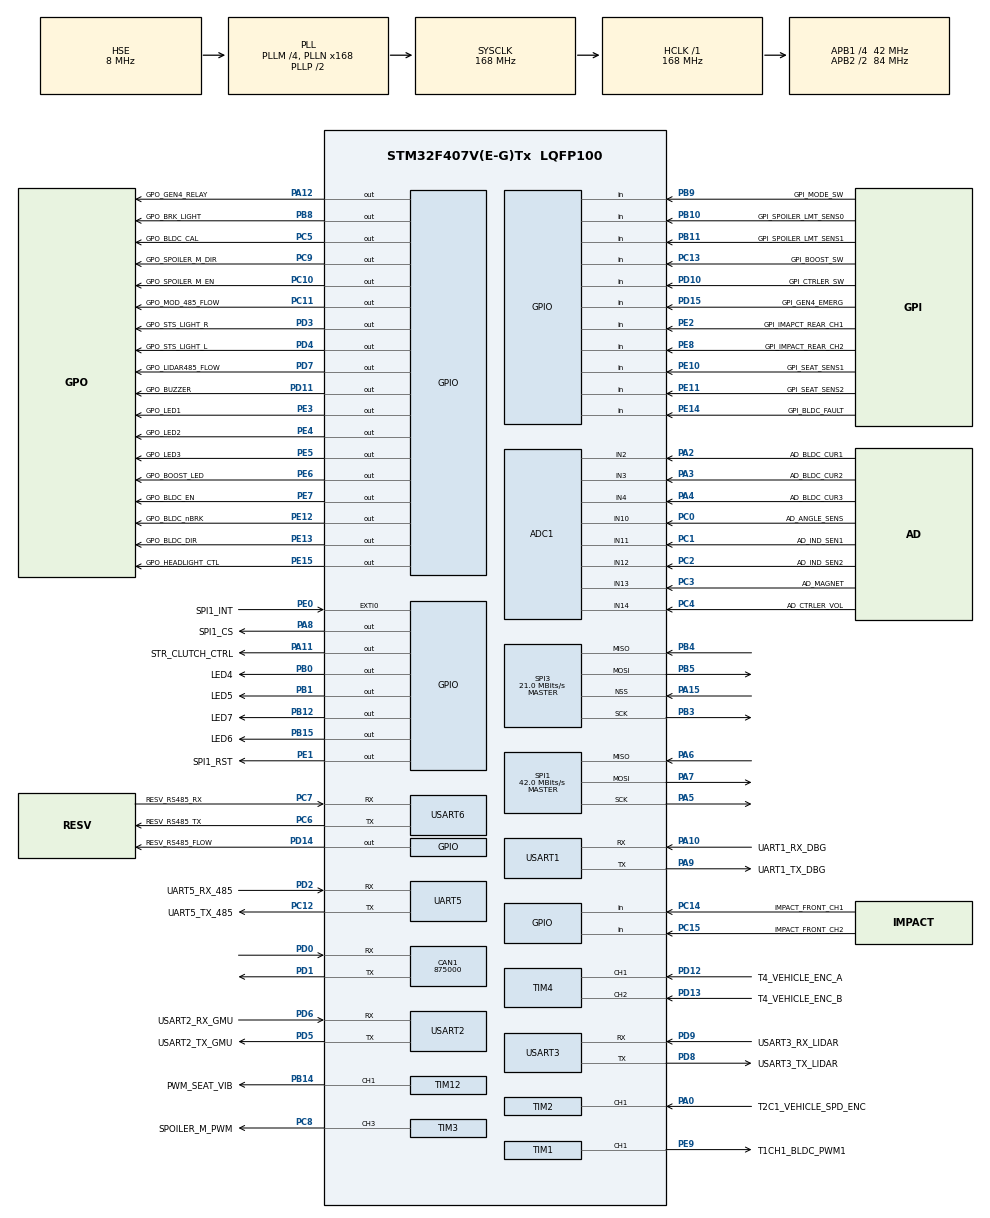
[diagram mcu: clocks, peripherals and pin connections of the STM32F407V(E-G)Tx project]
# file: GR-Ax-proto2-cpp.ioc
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ADC1.Channel-1\#ChannelRegularConversion=ADC_CHANNEL_2
ADC1.Channel-2\#ChannelRegularConversion=ADC_CHANNEL_3
ADC1.Channel-3\#ChannelRegularConversion=ADC_CHANNEL_4
ADC1.Channel-4\#ChannelRegularConversion=ADC_CHANNEL_11
ADC1.Channel-5\#ChannelRegularConversion=ADC_CHANNEL_12
ADC1.Channel-6\#ChannelRegularConversion=ADC_CHANNEL_14
ADC1.Channel-7\#ChannelRegularConversion=ADC_CHANNEL_TEMPSENSOR
ADC1.ContinuousConvMode=ENABLE
ADC1.DMAContinuousRequests=ENABLE
ADC1.DiscontinuousConvMode=DISABLE
ADC1.EOCSelection=ADC_EOC_SINGLE_CONV
ADC1.ExternalTrigConv=ADC_SOFTWARE_START
ADC1.NbrOfConversion=7
ADC1.NbrOfConversionFlag=1
ADC1.Rank-1\#ChannelRegularConversion=1
ADC1.Rank-2\#ChannelRegularConversion=2
ADC1.Rank-3\#ChannelRegularConversion=3
ADC1.Rank-4\#ChannelRegularConversion=4
ADC1.Rank-5\#ChannelRegularConversion=5
ADC1.Rank-6\#ChannelRegularConversion=6
ADC1.Rank-7\#ChannelRegularConversion=7
ADC1.SamplingTime-1\#ChannelRegularConversion=ADC_SAMPLETIME_112CYCLES
ADC1.SamplingTime-2\#ChannelRegularConversion=ADC_SAMPLETIME_112CYCLES
ADC1.SamplingTime-3\#ChannelRegularConversion=ADC_SAMPLETIME_112CYCLES
ADC1.SamplingTime-4\#ChannelRegularConversion=ADC_SAMPLETIME_112CYCLES
ADC1.SamplingTime-5\#ChannelRegularConversion=ADC_SAMPLETIME_112CYCLES
ADC1.SamplingTime-6\#ChannelRegularConversion=ADC_SAMPLETIME_112CYCLES
ADC1.SamplingTime-7\#ChannelRegularConversion=ADC_SAMPLETIME_112CYCLES
ADC1.master=1
CAN1.CalculateBaudRate=875000
CAN1.CalculateTimeBit=1142
CAN1.CalculateTimeQuantum=380.95238095238096
Dma.ADC1.0.Direction=DMA_PERIPH_TO_MEMORY
Dma.ADC1.0.FIFOMode=DMA_FIFOMODE_DISABLE
Dma.ADC1.0.Instance=DMA2_Stream4
Dma.ADC1.0.MemDataAlignment=DMA_MDATAALIGN_HALFWORD
Dma.ADC1.0.MemInc=DMA_MINC_ENABLE
Dma.ADC1.0.Mode=DMA_CIRCULAR
Dma.ADC1.0.PeriphDataAlignment=DMA_PDATAALIGN_HALFWORD
Dma.ADC1.0.PeriphInc=DMA_PINC_DISABLE
Dma.ADC1.0.Priority=DMA_PRIORITY_MEDIUM
Dma.Request0=ADC1
Dma.Request1=USART1_RX
Dma.Request10=UART5_TX
Dma.Request2=USART2_RX
Dma.Request3=USART3_RX
Dma.Request4=USART6_RX
Dma.Request5=USART1_TX
Dma.Request6=USART2_TX
Dma.Request7=USART3_TX
Dma.Request8=USART6_TX
Dma.Request9=UART5_RX
Dma.UART5_RX.9.Direction=DMA_PERIPH_TO_MEMORY
Dma.UART5_RX.9.FIFOMode=DMA_FIFOMODE_DISABLE
Dma.UART5_RX.9.Instance=DMA1_Stream0
Dma.UART5_RX.9.MemDataAlignment=DMA_MDATAALIGN_BYTE
Dma.UART5_RX.9.MemInc=DMA_MINC_ENABLE
Dma.UART5_RX.9.Mode=DMA_NORMAL
Dma.UART5_RX.9.PeriphDataAlignment=DMA_PDATAALIGN_BYTE
Dma.UART5_RX.9.PeriphInc=DMA_PINC_DISABLE
Dma.UART5_RX.9.Priority=DMA_PRIORITY_LOW
Dma.UART5_TX.10.Direction=DMA_MEMORY_TO_PERIPH
Dma.UART5_TX.10.FIFOMode=DMA_FIFOMODE_DISABLE
Dma.UART5_TX.10.Instance=DMA1_Stream7
Dma.UART5_TX.10.MemDataAlignment=DMA_MDATAALIGN_BYTE
Dma.UART5_TX.10.MemInc=DMA_MINC_ENABLE
Dma.UART5_TX.10.Mode=DMA_NORMAL
Dma.UART5_TX.10.PeriphDataAlignment=DMA_PDATAALIGN_BYTE
Dma.UART5_TX.10.PeriphInc=DMA_PINC_DISABLE
Dma.UART5_TX.10.Priority=DMA_PRIORITY_LOW
Dma.USART1_RX.1.Direction=DMA_PERIPH_TO_MEMORY
Dma.USART1_RX.1.FIFOMode=DMA_FIFOMODE_DISABLE
Dma.USART1_RX.1.Instance=DMA2_Stream2
Dma.USART1_RX.1.MemDataAlignment=DMA_MDATAALIGN_BYTE
Dma.USART1_RX.1.MemInc=DMA_MINC_ENABLE
Dma.USART1_RX.1.Mode=DMA_NORMAL
Dma.USART1_RX.1.PeriphDataAlignment=DMA_PDATAALIGN_BYTE
Dma.USART1_RX.1.PeriphInc=DMA_PINC_DISABLE
Dma.USART1_RX.1.Priority=DMA_PRIORITY_LOW
Dma.USART1_TX.5.Direction=DMA_MEMORY_TO_PERIPH
Dma.USART1_TX.5.FIFOMode=DMA_FIFOMODE_DISABLE
Dma.USART1_TX.5.Instance=DMA2_Stream7
Dma.USART1_TX.5.MemDataAlignment=DMA_MDATAALIGN_BYTE
Dma.USART1_TX.5.MemInc=DMA_MINC_ENABLE
Dma.USART1_TX.5.Mode=DMA_NORMAL
Dma.USART1_TX.5.PeriphDataAlignment=DMA_PDATAALIGN_BYTE
Dma.USART1_TX.5.PeriphInc=DMA_PINC_DISABLE
Dma.USART1_TX.5.Priority=DMA_PRIORITY_LOW
Dma.USART2_RX.2.Direction=DMA_PERIPH_TO_MEMORY
Dma.USART2_RX.2.FIFOMode=DMA_FIFOMODE_DISABLE
Dma.USART2_RX.2.Instance=DMA1_Stream5
Dma.USART2_RX.2.MemDataAlignment=DMA_MDATAALIGN_BYTE
Dma.USART2_RX.2.MemInc=DMA_MINC_ENABLE
Dma.USART2_RX.2.Mode=DMA_CIRCULAR
Dma.USART2_RX.2.PeriphDataAlignment=DMA_PDATAALIGN_BYTE
Dma.USART2_RX.2.PeriphInc=DMA_PINC_DISABLE
Dma.USART2_RX.2.Priority=DMA_PRIORITY_LOW
Dma.USART2_TX.6.Direction=DMA_MEMORY_TO_PERIPH
Dma.USART2_TX.6.FIFOMode=DMA_FIFOMODE_DISABLE
Dma.USART2_TX.6.Instance=DMA1_Stream6
Dma.USART2_TX.6.MemDataAlignment=DMA_MDATAALIGN_BYTE
Dma.USART2_TX.6.MemInc=DMA_MINC_ENABLE
Dma.USART2_TX.6.Mode=DMA_NORMAL
Dma.USART2_TX.6.PeriphDataAlignment=DMA_PDATAALIGN_BYTE
Dma.USART2_TX.6.PeriphInc=DMA_PINC_DISABLE
Dma.USART2_TX.6.Priority=DMA_PRIORITY_LOW
Dma.USART3_RX.3.Direction=DMA_PERIPH_TO_MEMORY
Dma.USART3_RX.3.FIFOMode=DMA_FIFOMODE_DISABLE
Dma.USART3_RX.3.Instance=DMA1_Stream1
Dma.USART3_RX.3.MemDataAlignment=DMA_MDATAALIGN_BYTE
Dma.USART3_RX.3.MemInc=DMA_MINC_ENABLE
Dma.USART3_RX.3.Mode=DMA_CIRCULAR
Dma.USART3_RX.3.PeriphDataAlignment=DMA_PDATAALIGN_BYTE
Dma.USART3_RX.3.PeriphInc=DMA_PINC_DISABLE
Dma.USART3_RX.3.Priority=DMA_PRIORITY_LOW
Dma.USART3_TX.7.Direction=DMA_MEMORY_TO_PERIPH
Dma.USART3_TX.7.FIFOMode=DMA_FIFOMODE_DISABLE
Dma.USART3_TX.7.Instance=DMA1_Stream3
Dma.USART3_TX.7.MemDataAlignment=DMA_MDATAALIGN_BYTE
Dma.USART3_TX.7.MemInc=DMA_MINC_ENABLE
Dma.USART3_TX.7.Mode=DMA_NORMAL
Dma.USART3_TX.7.PeriphDataAlignment=DMA_PDATAALIGN_BYTE
Dma.USART3_TX.7.PeriphInc=DMA_PINC_DISABLE
Dma.USART3_TX.7.Priority=DMA_PRIORITY_LOW
Dma.USART6_RX.4.Direction=DMA_PERIPH_TO_MEMORY
Dma.USART6_RX.4.FIFOMode=DMA_FIFOMODE_DISABLE
Dma.USART6_RX.4.Instance=DMA2_Stream1
Dma.USART6_RX.4.MemDataAlignment=DMA_MDATAALIGN_BYTE
Dma.USART6_RX.4.MemInc=DMA_MINC_ENABLE
Dma.USART6_RX.4.Mode=DMA_NORMAL
Dma.USART6_RX.4.PeriphDataAlignment=DMA_PDATAALIGN_BYTE
Dma.USART6_RX.4.PeriphInc=DMA_PINC_DISABLE
Dma.USART6_RX.4.Priority=DMA_PRIORITY_LOW
Dma.USART6_TX.8.Direction=DMA_MEMORY_TO_PERIPH
Dma.USART6_TX.8.FIFOMode=DMA_FIFOMODE_DISABLE
Dma.USART6_TX.8.Instance=DMA2_Stream6
Dma.USART6_TX.8.MemDataAlignment=DMA_MDATAALIGN_BYTE
Dma.USART6_TX.8.MemInc=DMA_MINC_ENABLE
Dma.USART6_TX.8.Mode=DMA_NORMAL
Dma.USART6_TX.8.PeriphDataAlignment=DMA_PDATAALIGN_BYTE
Dma.USART6_TX.8.PeriphInc=DMA_PINC_DISABLE
Dma.USART6_TX.8.Priority=DMA_PRIORITY_LOW
IWDG.Prescaler=IWDG_PRESCALER_16
Mcu.Family=STM32F4
Mcu.Name=STM32F407V(E-G)Tx
Mcu.Package=LQFP100
NVIC.CAN1_RX0_IRQn=true\:0\:0\:false\:false\:true\:true\:true\:true
NVIC.CAN1_RX1_IRQn=true\:0\:0\:false\:false\:true\:true\:true\:true
NVIC.CAN1_SCE_IRQn=true\:0\:0\:false\:false\:true\:true\:true\:true
NVIC.CAN1_TX_IRQn=true\:0\:0\:false\:false\:true\:true\:true\:true
NVIC.DMA1_Stream0_IRQn=true\:4\:0\:true\:false\:true\:false\:true\:true
NVIC.DMA1_Stream1_IRQn=true\:4\:0\:true\:false\:true\:false\:true\:true
NVIC.DMA1_Stream3_IRQn=true\:4\:0\:true\:false\:true\:false\:true\:true
NVIC.DMA1_Stream5_IRQn=true\:4\:0\:true\:false\:true\:false\:true\:true
NVIC.DMA1_Stream6_IRQn=true\:4\:0\:true\:false\:true\:false\:true\:true
NVIC.DMA1_Stream7_IRQn=true\:4\:0\:true\:false\:true\:false\:true\:true
NVIC.DMA2_Stream1_IRQn=true\:4\:0\:true\:false\:true\:false\:true\:true
NVIC.DMA2_Stream2_IRQn=true\:4\:0\:true\:false\:true\:false\:true\:true
NVIC.DMA2_Stream4_IRQn=true\:4\:0\:true\:false\:true\:false\:true\:true
NVIC.DMA2_Stream6_IRQn=true\:4\:0\:true\:false\:true\:false\:true\:true
NVIC.DMA2_Stream7_IRQn=true\:4\:0\:true\:false\:true\:false\:true\:true
NVIC.PriorityGroup=NVIC_PRIORITYGROUP_4
NVIC.TIM1_BRK_TIM9_IRQn=true\:4\:0\:true\:false\:true\:true\:true\:true
NVIC.TIM2_IRQn=true\:0\:0\:false\:false\:true\:true\:true\:true
NVIC.TIM6_DAC_IRQn=true\:0\:0\:false\:false\:true\:true\:true\:true
NVIC.TIM7_IRQn=true\:0\:0\:false\:false\:true\:true\:true\:true
NVIC.UART5_IRQn=true\:0\:0\:false\:false\:true\:true\:true\:true
NVIC.USART1_IRQn=true\:4\:0\:true\:false\:true\:true\:true\:true
NVIC.USART2_IRQn=true\:4\:0\:true\:false\:true\:true\:true\:true
NVIC.USART3_IRQn=true\:4\:0\:true\:false\:true\:true\:true\:true
NVIC.USART6_IRQn=true\:4\:0\:true\:false\:true\:true\:true\:true
PA0-WKUP.GPIO_Label=T2C1_VEHICLE_SPD_ENC
PA0-WKUP.Signal=S_TIM2_CH1_ETR
PA10.GPIO_Label=UART1_RX_DBG
PA10.Mode=Asynchronous
PA10.Signal=USART1_RX
PA11.GPIO_Label=STR_CLUTCH_CTRL
PA11.Signal=GPIO_Output
PA12.GPIO_Label=GPO_GEN4_RELAY
PA12.Signal=GPIO_Output
PA13.Mode=Serial_Wire
PA13.Signal=SYS_JTMS-SWDIO
PA14.Mode=Serial_Wire
PA14.Signal=SYS_JTCK-SWCLK
PA15.Mode=NSS_Signal_Hard_Input
PA15.Signal=SPI3_NSS
PA2.GPIO_Label=AD_BLDC_CUR1
PA2.Signal=ADCx_IN2
PA3.GPIO_Label=AD_BLDC_CUR2
PA3.Signal=ADCx_IN3
PA4.GPIO_Label=AD_BLDC_CUR3
PA4.Signal=ADCx_IN4
PA5.Mode=Full_Duplex_Master
PA5.Signal=SPI1_SCK
PA6.Mode=Full_Duplex_Master
PA6.Signal=SPI1_MISO
PA7.Mode=Full_Duplex_Master
PA7.Signal=SPI1_MOSI
PA8.GPIO_Label=SPI1_CS
PA8.Signal=GPIO_Output
PA9.GPIO_Label=UART1_TX_DBG
PA9.Mode=Asynchronous
PA9.Signal=USART1_TX
PB0.GPIO_Label=LED4
PB0.Signal=GPIO_Output
PB1.GPIO_Label=LED5
PB1.Signal=GPIO_Output
PB10.GPIO_Label=GPI_SPOILER_LMT_SENS0
PB10.Signal=GPIO_Input
PB11.GPIO_Label=GPI_SPOILER_LMT_SENS1
PB11.Signal=GPIO_Input
PB12.GPIO_Label=LED7
PB12.Signal=GPIO_Output
PB14.GPIO_Label=PWM_SEAT_VIB
PB14.Signal=S_TIM12_CH1
PB15.GPIO_Label=LED6
PB15.Signal=GPIO_Output
PB3.Mode=Full_Duplex_Master
PB3.Signal=SPI3_SCK
PB4.Mode=Full_Duplex_Master
PB4.Signal=SPI3_MISO
PB5.Mode=Full_Duplex_Master
PB5.Signal=SPI3_MOSI
PB8.GPIO_Label=GPO_BRK_LIGHT
PB8.Signal=GPIO_Output
PB9.GPIO_Label=GPI_MODE_SW
PB9.Signal=GPIO_Input
PC0.GPIO_Label=AD_ANGLE_SENS
PC0.Signal=ADCx_IN10
PC1.GPIO_Label=AD_IND_SEN1
PC1.Signal=ADCx_IN11
PC10.GPIO_Label=GPO_SPOILER_M_EN
PC10.Signal=GPIO_Output
PC11.GPIO_Label=GPO_MOD_485_FLOW
PC11.Signal=GPIO_Output
PC12.GPIO_Label=UART5_TX_485
PC12.Mode=Asynchronous
PC12.Signal=UART5_TX
PC13-ANTI_TAMP.GPIO_Label=GPI_BOOST_SW
PC13-ANTI_TAMP.Signal=GPIO_Input
PC14-OSC32_IN.GPIO_Label=IMPACT_FRONT_CH1
PC14-OSC32_IN.Signal=GPIO_Input
PC15-OSC32_OUT.GPIO_Label=IMPACT_FRONT_CH2
PC15-OSC32_OUT.Signal=GPIO_Input
PC2.GPIO_Label=AD_IND_SEN2
PC2.Signal=ADCx_IN12
PC3.GPIO_Label=AD_MAGNET
PC3.Signal=ADCx_IN13
PC4.GPIO_Label=AD_CTRLER_VOL
PC4.Signal=ADCx_IN14
PC5.GPIO_Label=GPO_BLDC_CAL
PC5.Signal=GPIO_Output
PC6.GPIO_Label=RESV_RS485_TX
PC6.Mode=Asynchronous
PC6.Signal=USART6_TX
PC7.GPIO_Label=RESV_RS485_RX
PC7.GPIO_PuPd=GPIO_NOPULL
PC7.Mode=Asynchronous
PC7.Signal=USART6_RX
PC8.GPIO_Label=SPOILER_M_PWM
PC8.Signal=S_TIM3_CH3
PC9.GPIO_Label=GPO_SPOILER_M_DIR
PC9.Signal=GPIO_Output
PD0.Mode=CAN_Activate
PD0.Signal=CAN1_RX
PD1.Mode=CAN_Activate
PD1.Signal=CAN1_TX
PD10.GPIO_Label=GPI_CTRLER_SW
PD10.Signal=GPIO_Input
PD11.GPIO_Label=GPO_BUZZER
PD11.Signal=GPIO_Output
PD12.GPIO_Label=T4_VEHICLE_ENC_A
PD12.GPIO_PuPd=GPIO_PULLUP
PD12.Signal=S_TIM4_CH1
PD13.GPIO_Label=T4_VEHICLE_ENC_B
PD13.GPIO_PuPd=GPIO_PULLUP
PD13.Signal=S_TIM4_CH2
PD14.GPIO_Label=RESV_RS485_FLOW
PD14.Signal=GPIO_Output
PD15.GPIO_Label=GPI_GEN4_EMERG
PD15.Signal=GPIO_Input
PD2.GPIO_Label=UART5_RX_485
PD2.Mode=Asynchronous
PD2.Signal=UART5_RX
PD3.GPIO_Label=GPO_STS_LIGHT_R
PD3.Signal=GPIO_Output
PD4.GPIO_Label=GPO_STS_LIGHT_L
PD4.Signal=GPIO_Output
PD5.GPIO_Label=USART2_TX_GMU
PD5.Mode=Asynchronous
PD5.Signal=USART2_TX
PD6.GPIO_Label=USART2_RX_GMU
PD6.Mode=Asynchronous
PD6.Signal=USART2_RX
PD7.GPIO_Label=GPO_LIDAR485_FLOW
PD7.Signal=GPIO_Output
PD8.GPIO_Label=USART3_TX_LIDAR
PD8.Mode=Asynchronous
PD8.Signal=USART3_TX
PD9.GPIO_Label=USART3_RX_LIDAR
PD9.Mode=Asynchronous
PD9.Signal=USART3_RX
PE0.GPIO_Label=SPI1_INT
PE0.Signal=GPXTI0
PE1.GPIO_Label=SPI1_RST
PE1.Signal=GPIO_Output
PE10.GPIO_Label=GPI_SEAT_SENS1
PE10.Signal=GPIO_Input
PE11.GPIO_Label=GPI_SEAT_SENS2
PE11.Signal=GPIO_Input
PE12.GPIO_Label=GPO_BLDC_nBRK
PE12.Signal=GPIO_Output
PE13.GPIO_Label=GPO_BLDC_DIR
PE13.Signal=GPIO_Output
PE14.GPIO_Label=GPI_BLDC_FAULT
PE14.GPIO_PuPd=GPIO_PULLUP
PE14.Signal=GPIO_Input
PE15.GPIO_Label=GPO_HEADLIGHT_CTL
PE15.Signal=GPIO_Output
PE2.GPIO_Label=GPI_IMAPCT_REAR_CH1
PE2.Signal=GPIO_Input
PE3.GPIO_Label=GPO_LED1
PE3.Signal=GPIO_Output
PE4.GPIO_Label=GPO_LED2
PE4.Signal=GPIO_Output
PE5.GPIO_Label=GPO_LED3
PE5.Signal=GPIO_Output
PE6.GPIO_Label=GPO_BOOST_LED
PE6.Signal=GPIO_Output
PE7.GPIO_Label=GPO_BLDC_EN
PE7.Signal=GPIO_Output
PE8.GPIO_Label=GPI_IMPACT_REAR_CH2
PE8.Signal=GPIO_Input
PE9.GPIO_Label=T1CH1_BLDC_PWM1
PE9.Signal=S_TIM1_CH1
PH0-OSC_IN.Mode=HSE-External-Oscillator
PH0-OSC_IN.Signal=RCC_OSC_IN
PH1-OSC_OUT.Mode=HSE-External-Oscillator
PH1-OSC_OUT.Signal=RCC_OSC_OUT
ProjectManager.HeapSize=0x200
ProjectManager.StackSize=0x800
ProjectManager.TargetToolchain=STM32CubeIDE
RCC.48MHZClocksFreq_Value=48000000
RCC.AHBFreq_Value=168000000
RCC.APB1CLKDivider=RCC_HCLK_DIV4
RCC.APB1Freq_Value=42000000
RCC.APB1TimFreq_Value=84000000
RCC.APB2CLKDivider=RCC_HCLK_DIV2
RCC.APB2Freq_Value=84000000
RCC.APB2TimFreq_Value=168000000
RCC.CortexFreq_Value=168000000
RCC.HCLKFreq_Value=168000000
RCC.HSE_VALUE=8000000
RCC.HSI_VALUE=16000000
RCC.LSE_VALUE=32768
RCC.PLLM=4
RCC.PLLN=168
RCC.PLLQ=7
RCC.PLLSourceVirtual=RCC_PLLSOURCE_HSE
RCC.SYSCLKFreq_VALUE=168000000
RCC.SYSCLKSource=RCC_SYSCLKSOURCE_PLLCLK
RCC.VCOOutputFreq_Value=336000000
SH.ADCx_IN10.0=ADC1_IN10,IN10
SH.ADCx_IN10.1=ADC2_IN10
SH.ADCx_IN11.0=ADC1_IN11,IN11
SH.ADCx_IN12.0=ADC1_IN12,IN12
SH.ADCx_IN13.0=ADC1_IN13,IN13
SH.ADCx_IN14.0=ADC1_IN14,IN14
SH.ADCx_IN2.0=ADC1_IN2,IN2
SH.ADCx_IN3.0=ADC1_IN3,IN3
SH.ADCx_IN4.0=ADC1_IN4,IN4
SH.S_TIM12_CH1.0=TIM12_CH1,Output Compare1 CH1
SH.S_TIM1_CH1.0=TIM1_CH1,PWM Generation1 CH1
SH.S_TIM2_CH1_ETR.0=TIM2_CH1,Input_Capture1_from_TI1
SH.S_TIM3_CH3.0=TIM3_CH3,PWM Generation3 CH3
SH.S_TIM4_CH1.0=TIM4_CH1,Encoder_Interface
SH.S_TIM4_CH2.0=TIM4_CH2,Encoder_Interface
SPI1.CalculateBaudRate=42.0 MBits/s
SPI1.Direction=SPI_DIRECTION_2LINES
SPI1.Mode=SPI_MODE_MASTER
SPI1.VirtualType=VM_MASTER
SPI3.CalculateBaudRate=21.0 MBits/s
SPI3.Direction=SPI_DIRECTION_2LINES
SPI3.Mode=SPI_MODE_MASTER
SPI3.VirtualNSS=VM_NSSHARD
SPI3.VirtualType=VM_MASTER
TIM1.Channel-PWM\ Generation1\ CH1=TIM_CHANNEL_1
TIM1.Period=4200-1
TIM1.Prescaler=2-1
TIM12.Channel-Output\ Compare1\ CH1=TIM_CHANNEL_1
TIM2.Channel-Input_Capture1_from_TI1=TIM_CHANNEL_1
TIM3.Channel-PWM\ Generation3\ CH3=TIM_CHANNEL_3
TIM4.EncoderMode=TIM_ENCODERMODE_TI12
TIM6.Period=1000-1
TIM6.Prescaler=84-1
TIM7.Period=1000-1
TIM7.Prescaler=840-1
UART5.VirtualMode=Asynchronous
USART1.VirtualMode=VM_ASYNC
USART2.VirtualMode=VM_ASYNC
USART3.VirtualMode=VM_ASYNC
USART6.VirtualMode=VM_ASYNC
VP_ADC1_TempSens_Input.Mode=IN-TempSens
VP_IWDG_VS_IWDG.Mode=IWDG_Activate
VP_TIM1_VS_ClockSourceINT.Mode=Internal
VP_TIM6_VS_ClockSourceINT.Mode=Enable_Timer
VP_TIM7_VS_ClockSourceINT.Mode=Enable_Timer
board=custom

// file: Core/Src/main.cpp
/* USER CODE BEGIN Header */
/**
  ******************************************************************************
  * @file           : main.c
  * @brief          : Main program body
  ******************************************************************************
  * @attention
  *
  * Copyright (c) 2024 STMicroelectronics.
  * All rights reserved.
  *
  * This software is licensed under terms that can be found in the LICENSE file
  * in the root directory of this software component.
  * If no LICENSE file comes with this software, it is provided AS-IS.
  *
  ******************************************************************************
  */
/* USER CODE END Header */
#include "main.h"

/* USER CODE BEGIN Includes */
#include "tiny_printf.h"
#include "portSTM32_uart.h"
//#include <iostream>
/* USER CODE END Includes */

ADC_HandleTypeDef hadc1;
DMA_HandleTypeDef hdma_adc1;

CAN_HandleTypeDef hcan1;

IWDG_HandleTypeDef hiwdg;

SPI_HandleTypeDef hspi1;
SPI_HandleTypeDef hspi3;

TIM_HandleTypeDef htim1;
TIM_HandleTypeDef htim2;
TIM_HandleTypeDef htim3;
TIM_HandleTypeDef htim4;
TIM_HandleTypeDef htim6;
TIM_HandleTypeDef htim7;
TIM_HandleTypeDef htim12;

UART_HandleTypeDef huart5;
UART_HandleTypeDef huart1;
UART_HandleTypeDef huart2;
UART_HandleTypeDef huart3;
UART_HandleTypeDef huart6;
DMA_HandleTypeDef hdma_uart5_rx;
DMA_HandleTypeDef hdma_uart5_tx;
DMA_HandleTypeDef hdma_usart1_rx;
DMA_HandleTypeDef hdma_usart1_tx;
DMA_HandleTypeDef hdma_usart2_rx;
DMA_HandleTypeDef hdma_usart2_tx;
DMA_HandleTypeDef hdma_usart3_rx;
DMA_HandleTypeDef hdma_usart3_tx;
DMA_HandleTypeDef hdma_usart6_rx;
DMA_HandleTypeDef hdma_usart6_tx;

/* USER CODE BEGIN PV */
uint8_t g_ucKernelStarted = 0;
/* USER CODE END PV */

void SystemClock_Config(void);
static void MX_GPIO_Init(void);
static void MX_DMA_Init(void);
static void MX_TIM1_Init(void);
static void MX_TIM4_Init(void);
static void MX_USART1_UART_Init(void);
static void MX_USART2_UART_Init(void);
static void MX_USART3_UART_Init(void);
static void MX_USART6_UART_Init(void);
static void MX_ADC1_Init(void);
static void MX_UART5_Init(void);
static void MX_CAN1_Init(void);
static void MX_IWDG_Init(void);
static void MX_TIM6_Init(void);
static void MX_TIM7_Init(void);
static void MX_SPI1_Init(void);
static void MX_SPI3_Init(void);
static void MX_TIM2_Init(void);
static void MX_TIM3_Init(void);
static void MX_TIM12_Init(void);

/* USER CODE BEGIN PFP */
void _putchar(char character)
{
  // send char to console etc.
  HAL_UART_Transmit(&huart1, (uint8_t*)(&character), 1, 20) ;
}
/* USER CODE END PFP */

/* USER CODE BEGIN 0 */
  portSTM32Uart stm32Uart;

extern void GR_EntryPoint();
/* USER CODE END 0 */

int main(void)
{

  /* MCU Configuration--------------------------------------------------------*/

  /* Reset of all peripherals, Initializes the Flash interface and the Systick. */
  HAL_Init();

  /* Configure the system clock */
  SystemClock_Config();

  /* Initialize all configured peripherals */
  MX_GPIO_Init();
  MX_DMA_Init();
  MX_TIM1_Init();
  MX_TIM4_Init();
  MX_USART1_UART_Init();
  MX_USART2_UART_Init();
  MX_USART3_UART_Init();
  MX_USART6_UART_Init();
  MX_ADC1_Init();
  MX_UART5_Init();
  MX_CAN1_Init();
  MX_IWDG_Init();
  MX_TIM6_Init();
  MX_TIM7_Init();
  MX_SPI1_Init();
  MX_SPI3_Init();
  MX_TIM2_Init();
  MX_TIM3_Init();
  MX_TIM12_Init();
  /* USER CODE BEGIN 2 */
  __HAL_DBGMCU_FREEZE_IWDG();

  if(__HAL_RCC_GET_FLAG(RCC_FLAG_IWDGRST) != RESET ){
    //RCC_ClearFlag();
    __HAL_RCC_CLEAR_RESET_FLAGS();
    //g_ucRstReason = RESET_REASON_WTDG;

    while(true){
      HAL_GPIO_TogglePin(GPO_LED1_GPIO_Port, GPO_LED1_Pin);
      HAL_GPIO_TogglePin(GPO_LED2_GPIO_Port, GPO_LED2_Pin);
      HAL_GPIO_TogglePin(GPO_LED3_GPIO_Port, GPO_LED3_Pin);
      HAL_GPIO_TogglePin(LED4_GPIO_Port, LED4_Pin);
      HAL_GPIO_TogglePin(LED5_GPIO_Port, LED5_Pin);
      HAL_GPIO_TogglePin(LED6_GPIO_Port, LED6_Pin);
      HAL_Delay(500);
    }
  }

  GR_EntryPoint();

  //Entry();
  g_ucKernelStarted = 1;
  PRINT_DBG("Starting Scheduler...\r\n");
  vTaskStartScheduler();
  /* USER CODE END 2 */

  /* Infinite loop */
  while (1)
  {

  }
}

void SystemClock_Config(void)
{
  RCC_OscInitTypeDef RCC_OscInitStruct = {0};
  RCC_ClkInitTypeDef RCC_ClkInitStruct = {0};

  /** Configure the main internal regulator output voltage
  */
  __HAL_RCC_PWR_CLK_ENABLE();
  __HAL_PWR_VOLTAGESCALING_CONFIG(PWR_REGULATOR_VOLTAGE_SCALE1);

  /** Initializes the RCC Oscillators according to the specified parameters
  * in the RCC_OscInitTypeDef structure.
  */
  RCC_OscInitStruct.OscillatorType = RCC_OSCILLATORTYPE_LSI|RCC_OSCILLATORTYPE_HSE;
  RCC_OscInitStruct.HSEState = RCC_HSE_ON;
  RCC_OscInitStruct.LSIState = RCC_LSI_ON;
  RCC_OscInitStruct.PLL.PLLState = RCC_PLL_ON;
  RCC_OscInitStruct.PLL.PLLSource = RCC_PLLSOURCE_HSE;
  RCC_OscInitStruct.PLL.PLLM = 4;
  RCC_OscInitStruct.PLL.PLLN = 168;
  RCC_OscInitStruct.PLL.PLLP = RCC_PLLP_DIV2;
  RCC_OscInitStruct.PLL.PLLQ = 7;
  if (HAL_RCC_OscConfig(&RCC_OscInitStruct) != HAL_OK)
  {
    Error_Handler();
  }

  /** Initializes the CPU, AHB and APB buses clocks
  */
  RCC_ClkInitStruct.ClockType = RCC_CLOCKTYPE_HCLK|RCC_CLOCKTYPE_SYSCLK
                              |RCC_CLOCKTYPE_PCLK1|RCC_CLOCKTYPE_PCLK2;
  RCC_ClkInitStruct.SYSCLKSource = RCC_SYSCLKSOURCE_PLLCLK;
  RCC_ClkInitStruct.AHBCLKDivider = RCC_SYSCLK_DIV1;
  RCC_ClkInitStruct.APB1CLKDivider = RCC_HCLK_DIV4;
  RCC_ClkInitStruct.APB2CLKDivider = RCC_HCLK_DIV2;

  if (HAL_RCC_ClockConfig(&RCC_ClkInitStruct, FLASH_LATENCY_5) != HAL_OK)
  {
    Error_Handler();
  }
}

static void MX_ADC1_Init(void)
{

  ADC_ChannelConfTypeDef sConfig = {0};

  /** Configure the global features of the ADC (Clock, Resolution, Data Alignment and number of conversion)
  */
  hadc1.Instance = ADC1;
  hadc1.Init.ClockPrescaler = ADC_CLOCK_SYNC_PCLK_DIV4;
  hadc1.Init.Resolution = ADC_RESOLUTION_12B;
  hadc1.Init.ScanConvMode = ENABLE;
  hadc1.Init.ContinuousConvMode = ENABLE;
  hadc1.Init.DiscontinuousConvMode = DISABLE;
  hadc1.Init.ExternalTrigConvEdge = ADC_EXTERNALTRIGCONVEDGE_NONE;
  hadc1.Init.ExternalTrigConv = ADC_SOFTWARE_START;
  hadc1.Init.DataAlign = ADC_DATAALIGN_RIGHT;
  hadc1.Init.NbrOfConversion = 9;
  hadc1.Init.DMAContinuousRequests = ENABLE;
  hadc1.Init.EOCSelection = ADC_EOC_SINGLE_CONV;
  if (HAL_ADC_Init(&hadc1) != HAL_OK)
  {
    Error_Handler();
  }

  /** Configure for the selected ADC regular channel its corresponding rank in the sequencer and its sample time.
  */
  sConfig.Channel = ADC_CHANNEL_2;
  sConfig.Rank = 1;
  sConfig.SamplingTime = ADC_SAMPLETIME_112CYCLES;
  if (HAL_ADC_ConfigChannel(&hadc1, &sConfig) != HAL_OK)
  {
    Error_Handler();
  }

  /** Configure for the selected ADC regular channel its corresponding rank in the sequencer and its sample time.
  */
  sConfig.Channel = ADC_CHANNEL_3;
  sConfig.Rank = 2;
  if (HAL_ADC_ConfigChannel(&hadc1, &sConfig) != HAL_OK)
  {
    Error_Handler();
  }

  /** Configure for the selected ADC regular channel its corresponding rank in the sequencer and its sample time.
  */
  sConfig.Channel = ADC_CHANNEL_4;
  sConfig.Rank = 3;
  if (HAL_ADC_ConfigChannel(&hadc1, &sConfig) != HAL_OK)
  {
    Error_Handler();
  }

  /** Configure for the selected ADC regular channel its corresponding rank in the sequencer and its sample time.
  */
  sConfig.Channel = ADC_CHANNEL_11;
  sConfig.Rank = 4;
  if (HAL_ADC_ConfigChannel(&hadc1, &sConfig) != HAL_OK)
  {
    Error_Handler();
  }

  /** Configure for the selected ADC regular channel its corresponding rank in the sequencer and its sample time.
  */
  sConfig.Channel = ADC_CHANNEL_12;
  sConfig.Rank = 5;
  if (HAL_ADC_ConfigChannel(&hadc1, &sConfig) != HAL_OK)
  {
    Error_Handler();
  }

  /** Configure for the selected ADC regular channel its corresponding rank in the sequencer and its sample time.
  */
  sConfig.Channel = ADC_CHANNEL_14;
  sConfig.Rank = 6;
  if (HAL_ADC_ConfigChannel(&hadc1, &sConfig) != HAL_OK)
  {
    Error_Handler();
  }

  /** Configure for the selected ADC regular channel its corresponding rank in the sequencer and its sample time.
  */
  sConfig.Channel = ADC_CHANNEL_10;
  sConfig.Rank = 7;
  if (HAL_ADC_ConfigChannel(&hadc1, &sConfig) != HAL_OK)
  {
    Error_Handler();
  }

  sConfig.Channel = ADC_CHANNEL_13;
  sConfig.Rank = 8;
  if (HAL_ADC_ConfigChannel(&hadc1, &sConfig) != HAL_OK)
  {
    Error_Handler();
  }

  sConfig.Channel = ADC_CHANNEL_TEMPSENSOR;
  sConfig.Rank = 9;
  if (HAL_ADC_ConfigChannel(&hadc1, &sConfig) != HAL_OK)
  {
    Error_Handler();
  }

}

static void MX_CAN1_Init(void)
{

  hcan1.Instance = CAN1;
  hcan1.Init.Prescaler = 14;
  hcan1.Init.Mode = CAN_MODE_NORMAL;
  hcan1.Init.SyncJumpWidth = CAN_SJW_1TQ;
  hcan1.Init.TimeSeg1 = CAN_BS1_3TQ;
  hcan1.Init.TimeSeg2 = CAN_BS2_8TQ;
  hcan1.Init.TimeTriggeredMode = DISABLE;
  hcan1.Init.AutoBusOff = ENABLE;
  hcan1.Init.AutoWakeUp = DISABLE;
  hcan1.Init.AutoRetransmission = ENABLE;
  hcan1.Init.ReceiveFifoLocked = DISABLE;
  hcan1.Init.TransmitFifoPriority = DISABLE;
  if (HAL_CAN_Init(&hcan1) != HAL_OK)
  {
    Error_Handler();
  }

}

static void MX_IWDG_Init(void)
{

  hiwdg.Instance = IWDG;
  hiwdg.Init.Prescaler = IWDG_PRESCALER_32;
  hiwdg.Init.Reload = 4095;
  if (HAL_IWDG_Init(&hiwdg) != HAL_OK)
  {
    Error_Handler();
  }

}

static void MX_SPI1_Init(void)
{

  /* SPI1 parameter configuration*/
  hspi1.Instance = SPI1;
  hspi1.Init.Mode = SPI_MODE_MASTER;
  hspi1.Init.Direction = SPI_DIRECTION_2LINES;
  hspi1.Init.DataSize = SPI_DATASIZE_8BIT;
  hspi1.Init.CLKPolarity = SPI_POLARITY_LOW;
  hspi1.Init.CLKPhase = SPI_PHASE_1EDGE;
  hspi1.Init.NSS = SPI_NSS_SOFT;
  hspi1.Init.BaudRatePrescaler = SPI_BAUDRATEPRESCALER_2;
  hspi1.Init.FirstBit = SPI_FIRSTBIT_MSB;
  hspi1.Init.TIMode = SPI_TIMODE_DISABLE;
  hspi1.Init.CRCCalculation = SPI_CRCCALCULATION_DISABLE;
  hspi1.Init.CRCPolynomial = 10;
  if (HAL_SPI_Init(&hspi1) != HAL_OK)
  {
    Error_Handler();
  }

}

static void MX_SPI3_Init(void)
{

  /* SPI3 parameter configuration*/
  hspi3.Instance = SPI3;
  hspi3.Init.Mode = SPI_MODE_MASTER;
  hspi3.Init.Direction = SPI_DIRECTION_2LINES;
  hspi3.Init.DataSize = SPI_DATASIZE_8BIT;
  hspi3.Init.CLKPolarity = SPI_POLARITY_LOW;
  hspi3.Init.CLKPhase = SPI_PHASE_1EDGE;
  hspi3.Init.NSS = SPI_NSS_SOFT;
  hspi3.Init.BaudRatePrescaler = SPI_BAUDRATEPRESCALER_2;
  hspi3.Init.FirstBit = SPI_FIRSTBIT_MSB;
  hspi3.Init.TIMode = SPI_TIMODE_DISABLE;
  hspi3.Init.CRCCalculation = SPI_CRCCALCULATION_DISABLE;
  hspi3.Init.CRCPolynomial = 10;
  if (HAL_SPI_Init(&hspi3) != HAL_OK)
  {
    Error_Handler();
  }

}

static void MX_TIM1_Init(void)
{

  TIM_ClockConfigTypeDef sClockSourceConfig = {0};
  TIM_MasterConfigTypeDef sMasterConfig = {0};
  TIM_OC_InitTypeDef sConfigOC = {0};
  TIM_BreakDeadTimeConfigTypeDef sBreakDeadTimeConfig = {0};

  htim1.Instance = TIM1;
  htim1.Init.Prescaler = 2-1;
  htim1.Init.CounterMode = TIM_COUNTERMODE_UP;
  htim1.Init.Period = 4200-1;
  htim1.Init.ClockDivision = TIM_CLOCKDIVISION_DIV1;
  htim1.Init.RepetitionCounter = 0;
  htim1.Init.AutoReloadPreload = TIM_AUTORELOAD_PRELOAD_DISABLE;
  if (HAL_TIM_Base_Init(&htim1) != HAL_OK)
  {
    Error_Handler();
  }
  sClockSourceConfig.ClockSource = TIM_CLOCKSOURCE_INTERNAL;
  if (HAL_TIM_ConfigClockSource(&htim1, &sClockSourceConfig) != HAL_OK)
  {
    Error_Handler();
  }
  if (HAL_TIM_PWM_Init(&htim1) != HAL_OK)
  {
    Error_Handler();
  }
  sMasterConfig.MasterOutputTrigger = TIM_TRGO_RESET;
  sMasterConfig.MasterSlaveMode = TIM_MASTERSLAVEMODE_DISABLE;
  if (HAL_TIMEx_MasterConfigSynchronization(&htim1, &sMasterConfig) != HAL_OK)
  {
    Error_Handler();
  }
  sConfigOC.OCMode = TIM_OCMODE_PWM1;
  sConfigOC.Pulse = 0;
  sConfigOC.OCPolarity = TIM_OCPOLARITY_HIGH;
  sConfigOC.OCNPolarity = TIM_OCNPOLARITY_HIGH;
  sConfigOC.OCFastMode = TIM_OCFAST_DISABLE;
  sConfigOC.OCIdleState = TIM_OCIDLESTATE_RESET;
  sConfigOC.OCNIdleState = TIM_OCNIDLESTATE_RESET;
  if (HAL_TIM_PWM_ConfigChannel(&htim1, &sConfigOC, TIM_CHANNEL_1) != HAL_OK)
  {
    Error_Handler();
  }
  sBreakDeadTimeConfig.OffStateRunMode = TIM_OSSR_DISABLE;
  sBreakDeadTimeConfig.OffStateIDLEMode = TIM_OSSI_DISABLE;
  sBreakDeadTimeConfig.LockLevel = TIM_LOCKLEVEL_OFF;
  sBreakDeadTimeConfig.DeadTime = 0;
  sBreakDeadTimeConfig.BreakState = TIM_BREAK_DISABLE;
  sBreakDeadTimeConfig.BreakPolarity = TIM_BREAKPOLARITY_HIGH;
  sBreakDeadTimeConfig.AutomaticOutput = TIM_AUTOMATICOUTPUT_DISABLE;
  if (HAL_TIMEx_ConfigBreakDeadTime(&htim1, &sBreakDeadTimeConfig) != HAL_OK)
  {
    Error_Handler();
  }
  HAL_TIM_MspPostInit(&htim1);

}

static void MX_TIM2_Init(void)
{

  TIM_MasterConfigTypeDef sMasterConfig = {0};
  TIM_IC_InitTypeDef sConfigIC = {0};

  htim2.Instance = TIM2;
  htim2.Init.Prescaler = 84-1;
  htim2.Init.CounterMode = TIM_COUNTERMODE_UP;
  htim2.Init.Period = 20000000-1;
  htim2.Init.ClockDivision = TIM_CLOCKDIVISION_DIV1;
  htim2.Init.AutoReloadPreload = TIM_AUTORELOAD_PRELOAD_DISABLE;
  if (HAL_TIM_IC_Init(&htim2) != HAL_OK)
  {
    Error_Handler();
  }
  sMasterConfig.MasterOutputTrigger = TIM_TRGO_RESET;
  sMasterConfig.MasterSlaveMode = TIM_MASTERSLAVEMODE_DISABLE;
  if (HAL_TIMEx_MasterConfigSynchronization(&htim2, &sMasterConfig) != HAL_OK)
  {
    Error_Handler();
  }
  sConfigIC.ICPolarity = TIM_INPUTCHANNELPOLARITY_RISING;
  sConfigIC.ICSelection = TIM_ICSELECTION_DIRECTTI;
  sConfigIC.ICPrescaler = TIM_ICPSC_DIV1;
  sConfigIC.ICFilter = 0;
  if (HAL_TIM_IC_ConfigChannel(&htim2, &sConfigIC, TIM_CHANNEL_1) != HAL_OK)
  {
    Error_Handler();
  }

}

static void MX_TIM3_Init(void)
{

  TIM_MasterConfigTypeDef sMasterConfig = {0};
  TIM_OC_InitTypeDef sConfigOC = {0};

  htim3.Instance = TIM3;
  htim3.Init.Prescaler = 2-1;
  htim3.Init.CounterMode = TIM_COUNTERMODE_UP;
  htim3.Init.Period = 2100-1;
  htim3.Init.ClockDivision = TIM_CLOCKDIVISION_DIV1;
  htim3.Init.AutoReloadPreload = TIM_AUTORELOAD_PRELOAD_DISABLE;
  if (HAL_TIM_PWM_Init(&htim3) != HAL_OK)
  {
    Error_Handler();
  }
  sMasterConfig.MasterOutputTrigger = TIM_TRGO_RESET;
  sMasterConfig.MasterSlaveMode = TIM_MASTERSLAVEMODE_DISABLE;
  if (HAL_TIMEx_MasterConfigSynchronization(&htim3, &sMasterConfig) != HAL_OK)
  {
    Error_Handler();
  }
  sConfigOC.OCMode = TIM_OCMODE_PWM1;
  sConfigOC.Pulse = 0;
  sConfigOC.OCPolarity = TIM_OCPOLARITY_HIGH;
  sConfigOC.OCFastMode = TIM_OCFAST_DISABLE;
  if (HAL_TIM_PWM_ConfigChannel(&htim3, &sConfigOC, TIM_CHANNEL_3) != HAL_OK)
  {
    Error_Handler();
  }
  HAL_TIM_MspPostInit(&htim3);

}

static void MX_TIM4_Init(void)
{

  TIM_Encoder_InitTypeDef sConfig = {0};
  TIM_MasterConfigTypeDef sMasterConfig = {0};

  htim4.Instance = TIM4;
  htim4.Init.Prescaler = 0;
  htim4.Init.CounterMode = TIM_COUNTERMODE_UP;
  htim4.Init.Period = 65535;
  htim4.Init.ClockDivision = TIM_CLOCKDIVISION_DIV1;
  htim4.Init.AutoReloadPreload = TIM_AUTORELOAD_PRELOAD_DISABLE;
  sConfig.EncoderMode = TIM_ENCODERMODE_TI12;
  sConfig.IC1Polarity = TIM_ICPOLARITY_RISING;
  sConfig.IC1Selection = TIM_ICSELECTION_DIRECTTI;
  sConfig.IC1Prescaler = TIM_ICPSC_DIV1;
  sConfig.IC1Filter = 0;
  sConfig.IC2Polarity = TIM_ICPOLARITY_RISING;
  sConfig.IC2Selection = TIM_ICSELECTION_DIRECTTI;
  sConfig.IC2Prescaler = TIM_ICPSC_DIV1;
  sConfig.IC2Filter = 0;
  if (HAL_TIM_Encoder_Init(&htim4, &sConfig) != HAL_OK)
  {
    Error_Handler();
  }
  sMasterConfig.MasterOutputTrigger = TIM_TRGO_RESET;
  sMasterConfig.MasterSlaveMode = TIM_MASTERSLAVEMODE_DISABLE;
  if (HAL_TIMEx_MasterConfigSynchronization(&htim4, &sMasterConfig) != HAL_OK)
  {
    Error_Handler();
  }

}

static void MX_TIM6_Init(void)
{

  TIM_MasterConfigTypeDef sMasterConfig = {0};

  htim6.Instance = TIM6;
  htim6.Init.Prescaler = 84-1;
  htim6.Init.CounterMode = TIM_COUNTERMODE_UP;
  htim6.Init.Period = 1000-1;
  htim6.Init.AutoReloadPreload = TIM_AUTORELOAD_PRELOAD_DISABLE;
  if (HAL_TIM_Base_Init(&htim6) != HAL_OK)
  {
    Error_Handler();
  }
  sMasterConfig.MasterOutputTrigger = TIM_TRGO_RESET;
  sMasterConfig.MasterSlaveMode = TIM_MASTERSLAVEMODE_DISABLE;
  if (HAL_TIMEx_MasterConfigSynchronization(&htim6, &sMasterConfig) != HAL_OK)
  {
    Error_Handler();
  }

}

static void MX_TIM7_Init(void)
{

  TIM_MasterConfigTypeDef sMasterConfig = {0};

  htim7.Instance = TIM7;
  htim7.Init.Prescaler = 840-1;
  htim7.Init.CounterMode = TIM_COUNTERMODE_UP;
  htim7.Init.Period = 1000-1;
  htim7.Init.AutoReloadPreload = TIM_AUTORELOAD_PRELOAD_DISABLE;
  if (HAL_TIM_Base_Init(&htim7) != HAL_OK)
  {
    Error_Handler();
  }
  sMasterConfig.MasterOutputTrigger = TIM_TRGO_RESET;
  sMasterConfig.MasterSlaveMode = TIM_MASTERSLAVEMODE_DISABLE;
  if (HAL_TIMEx_MasterConfigSynchronization(&htim7, &sMasterConfig) != HAL_OK)
  {
    Error_Handler();
  }

}

static void MX_TIM12_Init(void)
{

  TIM_OC_InitTypeDef sConfigOC = {0};

  htim12.Instance = TIM12;
  htim12.Init.Prescaler = 0;
  htim12.Init.CounterMode = TIM_COUNTERMODE_UP;
  htim12.Init.Period = 65535;
  htim12.Init.ClockDivision = TIM_CLOCKDIVISION_DIV1;
  htim12.Init.AutoReloadPreload = TIM_AUTORELOAD_PRELOAD_DISABLE;
  if (HAL_TIM_OC_Init(&htim12) != HAL_OK)
  {
    Error_Handler();
  }
  sConfigOC.OCMode = TIM_OCMODE_TIMING;
  sConfigOC.Pulse = 0;
  sConfigOC.OCPolarity = TIM_OCPOLARITY_HIGH;
  sConfigOC.OCFastMode = TIM_OCFAST_DISABLE;
  if (HAL_TIM_OC_ConfigChannel(&htim12, &sConfigOC, TIM_CHANNEL_1) != HAL_OK)
  {
    Error_Handler();
  }
  HAL_TIM_MspPostInit(&htim12);

}

static void MX_UART5_Init(void)
{

  huart5.Instance = UART5;
  huart5.Init.BaudRate = 115200;
  huart5.Init.WordLength = UART_WORDLENGTH_8B;
  huart5.Init.StopBits = UART_STOPBITS_1;
  huart5.Init.Parity = UART_PARITY_NONE;
  huart5.Init.Mode = UART_MODE_TX_RX;
  huart5.Init.HwFlowCtl = UART_HWCONTROL_NONE;
  huart5.Init.OverSampling = UART_OVERSAMPLING_16;
  if (HAL_UART_Init(&huart5) != HAL_OK)
  {
    Error_Handler();
  }

}

static void MX_USART1_UART_Init(void)
{

  huart1.Instance = USART1;
  huart1.Init.BaudRate = 115200;  //230400
  huart1.Init.WordLength = UART_WORDLENGTH_8B;
  huart1.Init.StopBits = UART_STOPBITS_1;
  huart1.Init.Parity = UART_PARITY_NONE;
  huart1.Init.Mode = UART_MODE_TX_RX;
  huart1.Init.HwFlowCtl = UART_HWCONTROL_NONE;
  huart1.Init.OverSampling = UART_OVERSAMPLING_16;
  if (HAL_UART_Init(&huart1) != HAL_OK)
  {
    Error_Handler();
  }

}

static void MX_USART2_UART_Init(void)
{

  huart2.Instance = USART2;
  huart2.Init.BaudRate = 115200;
  huart2.Init.WordLength = UART_WORDLENGTH_8B;
  huart2.Init.StopBits = UART_STOPBITS_1;
  huart2.Init.Parity = UART_PARITY_NONE;
  huart2.Init.Mode = UART_MODE_TX_RX;
  huart2.Init.HwFlowCtl = UART_HWCONTROL_NONE;
  huart2.Init.OverSampling = UART_OVERSAMPLING_16;
  if (HAL_UART_Init(&huart2) != HAL_OK)
  {
    Error_Handler();
  }

}

static void MX_USART3_UART_Init(void)
{

  huart3.Instance = USART3;
  huart3.Init.BaudRate = 115200;
  huart3.Init.WordLength = UART_WORDLENGTH_8B;
  huart3.Init.StopBits = UART_STOPBITS_1;
  huart3.Init.Parity = UART_PARITY_NONE;
  huart3.Init.Mode = UART_MODE_TX_RX;
  huart3.Init.HwFlowCtl = UART_HWCONTROL_NONE;
  huart3.Init.OverSampling = UART_OVERSAMPLING_16;
  if (HAL_UART_Init(&huart3) != HAL_OK)
  {
    Error_Handler();
  }

}

static void MX_USART6_UART_Init(void)
{

  huart6.Instance = USART6;
  huart6.Init.BaudRate = 115200;
  huart6.Init.WordLength = UART_WORDLENGTH_8B;
  huart6.Init.StopBits = UART_STOPBITS_1;
  huart6.Init.Parity = UART_PARITY_NONE;
  huart6.Init.Mode = UART_MODE_TX_RX;
  huart6.Init.HwFlowCtl = UART_HWCONTROL_NONE;
  huart6.Init.OverSampling = UART_OVERSAMPLING_16;
  if (HAL_UART_Init(&huart6) != HAL_OK)
  {
    Error_Handler();
  }

}

static void MX_DMA_Init(void)
{

  /* DMA controller clock enable */
  __HAL_RCC_DMA2_CLK_ENABLE();
  __HAL_RCC_DMA1_CLK_ENABLE();

  /* DMA interrupt init */
  /* DMA1_Stream0_IRQn interrupt configuration */
  HAL_NVIC_SetPriority(DMA1_Stream0_IRQn, 6, 0);
  HAL_NVIC_EnableIRQ(DMA1_Stream0_IRQn);
  /* DMA1_Stream1_IRQn interrupt configuration */
  HAL_NVIC_SetPriority(DMA1_Stream1_IRQn, 6, 0);
  HAL_NVIC_EnableIRQ(DMA1_Stream1_IRQn);
  /* DMA1_Stream3_IRQn interrupt configuration */
  HAL_NVIC_SetPriority(DMA1_Stream3_IRQn, 6, 0);
  HAL_NVIC_EnableIRQ(DMA1_Stream3_IRQn);
  /* DMA1_Stream5_IRQn interrupt configuration */
  HAL_NVIC_SetPriority(DMA1_Stream5_IRQn, 6, 0);
  HAL_NVIC_EnableIRQ(DMA1_Stream5_IRQn);
  /* DMA1_Stream6_IRQn interrupt configuration */
  HAL_NVIC_SetPriority(DMA1_Stream6_IRQn, 6, 0);
  HAL_NVIC_EnableIRQ(DMA1_Stream6_IRQn);
  /* DMA1_Stream7_IRQn interrupt configuration */
  HAL_NVIC_SetPriority(DMA1_Stream7_IRQn, 6, 0);
  HAL_NVIC_EnableIRQ(DMA1_Stream7_IRQn);
  /* DMA2_Stream1_IRQn interrupt configuration */
  HAL_NVIC_SetPriority(DMA2_Stream1_IRQn, 6, 0);
  HAL_NVIC_EnableIRQ(DMA2_Stream1_IRQn);
  /* DMA2_Stream2_IRQn interrupt configuration */
  HAL_NVIC_SetPriority(DMA2_Stream2_IRQn, 6, 0);
  HAL_NVIC_EnableIRQ(DMA2_Stream2_IRQn);
  /* DMA2_Stream4_IRQn interrupt configuration */
  HAL_NVIC_SetPriority(DMA2_Stream4_IRQn, 6, 0);
  HAL_NVIC_EnableIRQ(DMA2_Stream4_IRQn);
  /* DMA2_Stream6_IRQn interrupt configuration */
  HAL_NVIC_SetPriority(DMA2_Stream6_IRQn, 6, 0);
  HAL_NVIC_EnableIRQ(DMA2_Stream6_IRQn);
  /* DMA2_Stream7_IRQn interrupt configuration */
  HAL_NVIC_SetPriority(DMA2_Stream7_IRQn, 6, 0);
  HAL_NVIC_EnableIRQ(DMA2_Stream7_IRQn);

  HAL_NVIC_SetPriority(DMA1_Stream4_IRQn, 6, 0);
    HAL_NVIC_EnableIRQ(DMA1_Stream4_IRQn);

}

static void MX_GPIO_Init(void)
{
  GPIO_InitTypeDef GPIO_InitStruct = {0};

  /* GPIO Ports Clock Enable */
  __HAL_RCC_GPIOE_CLK_ENABLE();
  __HAL_RCC_GPIOC_CLK_ENABLE();
  __HAL_RCC_GPIOH_CLK_ENABLE();
  __HAL_RCC_GPIOA_CLK_ENABLE();
  __HAL_RCC_GPIOB_CLK_ENABLE();
  __HAL_RCC_GPIOD_CLK_ENABLE();

  /*Configure GPIO pin Output Level */
  HAL_GPIO_WritePin(GPIOE, GPO_LED1_Pin|GPO_LED2_Pin|GPO_LED3_Pin|GPO_BOOST_LED_Pin
                          |GPO_BLDC_EN_Pin|GPO_BLDC_nBRK_Pin|GPO_BLDC_DIR_Pin|SPI1_RST_Pin, GPIO_PIN_RESET);

  /*Configure GPIO pin Output Level */
  HAL_GPIO_WritePin(GPIOC, GPO_BLDC_CAL_Pin|GPO_SPOILER_M_DIR_Pin|GPO_SPOILER_M_EN_Pin|GPO_MOD_485_FLOW_Pin, GPIO_PIN_RESET);

  /*Configure GPIO pin Output Level */
  HAL_GPIO_WritePin(GPIOB, LED4_Pin|LED5_Pin|LED7_Pin|LED6_Pin
                          |GPO_BRK_LIGHT_Pin, GPIO_PIN_RESET);

  /*Configure GPIO pin Output Level */
  HAL_GPIO_WritePin(GPIOD, GPO_BUZZER_Pin|GPO_RESV_RS485_FLOW_Pin|GPO_STS_LIGHT_R_Pin|GPO_STS_LIGHT_L_Pin, GPIO_PIN_RESET);

  /*Configure GPIO pin Output Level */
  HAL_GPIO_WritePin(GPIOA, SPI1_CS_Pin|STR_CLUTCH_CTRL_Pin|GPO_GEN4_RELAY_Pin, GPIO_PIN_RESET);

  /*Configure GPIO pins : GPO_LED1_Pin GPO_LED2_Pin GPO_LED3_Pin GPO_BOOST_LED_Pin
                           GPO_BLDC_EN_Pin GPO_BLDC_nBRK_Pin GPO_BLDC_DIR_Pin SPI1_RST_Pin */
  GPIO_InitStruct.Pin = GPO_LED1_Pin|GPO_LED2_Pin|GPO_LED3_Pin|GPO_BOOST_LED_Pin
                          |GPO_BLDC_EN_Pin|GPO_BLDC_nBRK_Pin|GPO_BLDC_DIR_Pin|SPI1_RST_Pin;
  GPIO_InitStruct.Mode = GPIO_MODE_OUTPUT_PP;
  GPIO_InitStruct.Pull = GPIO_NOPULL;
  GPIO_InitStruct.Speed = GPIO_SPEED_FREQ_LOW;
  HAL_GPIO_Init(GPIOE, &GPIO_InitStruct);

  /*Configure GPIO pin : GPI_BOOST_SW_Pin */
  GPIO_InitStruct.Pin = GPI_BOOST_SW_Pin;
  GPIO_InitStruct.Mode = GPIO_MODE_INPUT;
  GPIO_InitStruct.Pull = GPIO_NOPULL;
  HAL_GPIO_Init(GPI_BOOST_SW_GPIO_Port, &GPIO_InitStruct);

  /*Configure GPIO pin : AD_ANGLE_SENS_Pin */
  GPIO_InitStruct.Pin = AD_ANGLE_SENS_Pin;
  GPIO_InitStruct.Mode = GPIO_MODE_ANALOG;
  GPIO_InitStruct.Pull = GPIO_NOPULL;
  HAL_GPIO_Init(AD_ANGLE_SENS_GPIO_Port, &GPIO_InitStruct);

  /*Configure GPIO pins : GPO_BLDC_CAL_Pin GPO_SPOILER_M_DIR_Pin GPO_SPOILER_M_EN_Pin GPO_MOD_485_FLOW_Pin */
  GPIO_InitStruct.Pin = GPO_BLDC_CAL_Pin|GPO_SPOILER_M_DIR_Pin|GPO_SPOILER_M_EN_Pin|GPO_MOD_485_FLOW_Pin;
  GPIO_InitStruct.Mode = GPIO_MODE_OUTPUT_PP;
  GPIO_InitStruct.Pull = GPIO_NOPULL;
  GPIO_InitStruct.Speed = GPIO_SPEED_FREQ_LOW;
  HAL_GPIO_Init(GPIOC, &GPIO_InitStruct);

  /*Configure GPIO pins : LED4_Pin LED5_Pin LED7_Pin LED6_Pin
                           GPO_BRK_LIGHT_Pin */
  GPIO_InitStruct.Pin = LED4_Pin|LED5_Pin|LED7_Pin|LED6_Pin
                          |GPO_BRK_LIGHT_Pin;
  GPIO_InitStruct.Mode = GPIO_MODE_OUTPUT_PP;
  GPIO_InitStruct.Pull = GPIO_NOPULL;
  GPIO_InitStruct.Speed = GPIO_SPEED_FREQ_LOW;
  HAL_GPIO_Init(GPIOB, &GPIO_InitStruct);

  /*Configure GPIO pins : GPI_SEAT_SENS1_Pin GPI_SEAT_SENS2_Pin */
  GPIO_InitStruct.Pin = GPI_SEAT_SENS1_Pin|GPI_SEAT_SENS2_Pin;
  GPIO_InitStruct.Mode = GPIO_MODE_INPUT;
  GPIO_InitStruct.Pull = GPIO_NOPULL;
  HAL_GPIO_Init(GPIOE, &GPIO_InitStruct);

  /*Configure GPIO pin : GPI_BLDC_FAULT_Pin */
  GPIO_InitStruct.Pin = GPI_BLDC_FAULT_Pin;
  GPIO_InitStruct.Mode = GPIO_MODE_INPUT;
  GPIO_InitStruct.Pull = GPIO_PULLUP;
  HAL_GPIO_Init(GPI_BLDC_FAULT_GPIO_Port, &GPIO_InitStruct);

  /*Configure GPIO pins : GPI_SPOILER_LMT_SENS0_Pin GPI_SPOILER_LMT_SENS1_Pin GPI_MODE_SW_Pin */
  GPIO_InitStruct.Pin = GPI_SPOILER_LMT_SENS0_Pin|GPI_SPOILER_LMT_SENS1_Pin|GPI_MODE_SW_Pin;
  GPIO_InitStruct.Mode = GPIO_MODE_INPUT;
  GPIO_InitStruct.Pull = GPIO_NOPULL;
  HAL_GPIO_Init(GPIOB, &GPIO_InitStruct);

  /*Configure GPIO pins : GPI_CTRLER_SW_Pin GPI_GEN4_EMERG_Pin */
  GPIO_InitStruct.Pin = GPI_CTRLER_SW_Pin|GPI_GEN4_EMERG_Pin;
  GPIO_InitStruct.Mode = GPIO_MODE_INPUT;
  GPIO_InitStruct.Pull = GPIO_NOPULL;
  HAL_GPIO_Init(GPIOD, &GPIO_InitStruct);

  /*Configure GPIO pins : GPO_BUZZER_Pin GPO_HANDLE_FLOW_Pin GPO_STS_LIGHT_R_Pin GPO_STS_LIGHT_L_Pin */
  GPIO_InitStruct.Pin = GPO_BUZZER_Pin|GPO_RESV_RS485_FLOW_Pin|GPO_STS_LIGHT_R_Pin|GPO_STS_LIGHT_L_Pin;
  GPIO_InitStruct.Mode = GPIO_MODE_OUTPUT_PP;
  GPIO_InitStruct.Pull = GPIO_NOPULL;
  GPIO_InitStruct.Speed = GPIO_SPEED_FREQ_LOW;
  HAL_GPIO_Init(GPIOD, &GPIO_InitStruct);

  /*Configure GPIO pins : SPI1_CS_Pin STR_CLUTCH_CTRL_Pin GPO_GEN4_RELAY_Pin */
  GPIO_InitStruct.Pin = SPI1_CS_Pin|STR_CLUTCH_CTRL_Pin|GPO_GEN4_RELAY_Pin;
  GPIO_InitStruct.Mode = GPIO_MODE_OUTPUT_PP;
  GPIO_InitStruct.Pull = GPIO_NOPULL;
  GPIO_InitStruct.Speed = GPIO_SPEED_FREQ_LOW;
  HAL_GPIO_Init(GPIOA, &GPIO_InitStruct);

  /*Configure GPIO pin : SPI1_INT_Pin */
  GPIO_InitStruct.Pin = SPI1_INT_Pin;
  GPIO_InitStruct.Mode = GPIO_MODE_IT_RISING;
  GPIO_InitStruct.Pull = GPIO_NOPULL;
  HAL_GPIO_Init(SPI1_INT_GPIO_Port, &GPIO_InitStruct);

/* USER CODE BEGIN MX_GPIO_Init_2 */

  // 충격감지모듈 입력
  GPIO_InitStruct.Pin = GPI_IMPACT_REAR_CH1_Pin | GPI_IMPACT_REAR_CH2_Pin ;
  GPIO_InitStruct.Mode = GPIO_MODE_INPUT;
  GPIO_InitStruct.Pull = GPIO_NOPULL;
  HAL_GPIO_Init(GPIOE, &GPIO_InitStruct);

  // 헤드라이트 제어
  GPIO_InitStruct.Pin = GPO_HEADLIGHT_CTL_Pin ;
  GPIO_InitStruct.Mode = GPIO_MODE_OUTPUT_PP;
  GPIO_InitStruct.Pull = GPIO_NOPULL;
  HAL_GPIO_Init(GPIOE, &GPIO_InitStruct);

  // 충격감지모듈 입력
  GPIO_InitStruct.Pin = GPI_IMPACT_FRONT_CH1_Pin | GPI_IMPACT_FRONT_CH2_Pin ;
  GPIO_InitStruct.Mode = GPIO_MODE_INPUT;
  GPIO_InitStruct.Pull = GPIO_NOPULL;
  HAL_GPIO_Init(GPIOC, &GPIO_InitStruct);

  // 라이다 RS485 flow 제어
  GPIO_InitStruct.Pin = GPI_LIDAR_485_FLOW_Pin ;
  GPIO_InitStruct.Mode = GPIO_MODE_OUTPUT_PP;
  GPIO_InitStruct.Pull = GPIO_NOPULL;
  HAL_GPIO_Init(GPIOD, &GPIO_InitStruct);

  GPIO_InitStruct.Pin = GPIO_PIN_14 ;
  GPIO_InitStruct.Mode = GPIO_MODE_OUTPUT_PP;
  GPIO_InitStruct.Pull = GPIO_NOPULL;
  HAL_GPIO_Init(GPIOD, &GPIO_InitStruct);

  GPIO_InitStruct.Pin = GPIO_PIN_15;
  GPIO_InitStruct.Mode = GPIO_MODE_OUTPUT_PP;
  GPIO_InitStruct.Pull = GPIO_NOPULL;
  GPIO_InitStruct.Speed = GPIO_SPEED_FREQ_VERY_HIGH;
  GPIO_InitStruct.Alternate = GPIO_AF6_SPI3;
  HAL_GPIO_Init(GPIOA, &GPIO_InitStruct);
/* USER CODE END MX_GPIO_Init_2 */
}

/* USER CODE BEGIN 4 */
void vApplicationGetIdleTaskMemory( StaticTask_t **ppxIdleTaskTCBBuffer,
                                    StackType_t **ppxIdleTaskStackBuffer,
                                    uint32_t *pulIdleTaskStackSize )
{
    /* If the buffers to be provided to the Idle task are declared inside this
       function then they must be declared static - otherwise they will be allocated on
       the stack and so not exists after this function exits. */
    static StaticTask_t xIdleTaskTCB;
    static StackType_t uxIdleTaskStack[ configMINIMAL_STACK_SIZE ];

    /* Pass out a pointer to the StaticTask_t structure in which the Idle task's
       state will be stored. */
    *ppxIdleTaskTCBBuffer = &xIdleTaskTCB;

    /* Pass out the array that will be used as the Idle task's stack. */
    *ppxIdleTaskStackBuffer = uxIdleTaskStack;

    /* Pass out the size of the array pointed to by *ppxIdleTaskStackBuffer.
       Note that, as the array is necessarily of type StackType_t,
       configMINIMAL_STACK_SIZE is specified in words, not bytes. */
    *pulIdleTaskStackSize = configMINIMAL_STACK_SIZE;
}

void LidarPinReset(){
  GPIO_InitTypeDef GPIO_InitStruct = {0};
  // TX 핀 (UART1_TX)
    GPIO_InitStruct.Pin = USART3_TX_LIDAR_Pin;  // PA9 가정
    GPIO_InitStruct.Mode = GPIO_MODE_OUTPUT_PP;
    GPIO_InitStruct.Pull = GPIO_PULLUP;
    GPIO_InitStruct.Speed = GPIO_SPEED_FREQ_LOW;
    HAL_GPIO_Init(GPIOD, &GPIO_InitStruct);

    // RX 핀 (UART1_RX)
    GPIO_InitStruct.Pin = USART3_RX_LIDAR_Pin;  // PA10 가정
    GPIO_InitStruct.Mode = GPIO_MODE_INPUT;
    GPIO_InitStruct.Pull = GPIO_PULLUP;
    HAL_GPIO_Init(GPIOD, &GPIO_InitStruct);

    // 3. TX를 IDLE 상태(High)로 설정
    HAL_GPIO_WritePin(GPIOD, USART3_TX_LIDAR_Pin, GPIO_PIN_RESET);
    HAL_GPIO_WritePin(GPIOD, USART3_RX_LIDAR_Pin, GPIO_PIN_SET);

}

/* USER CODE END 4 */

void Error_Handler(void)
{
  __disable_irq();
  while (1)
  {
  }
}
